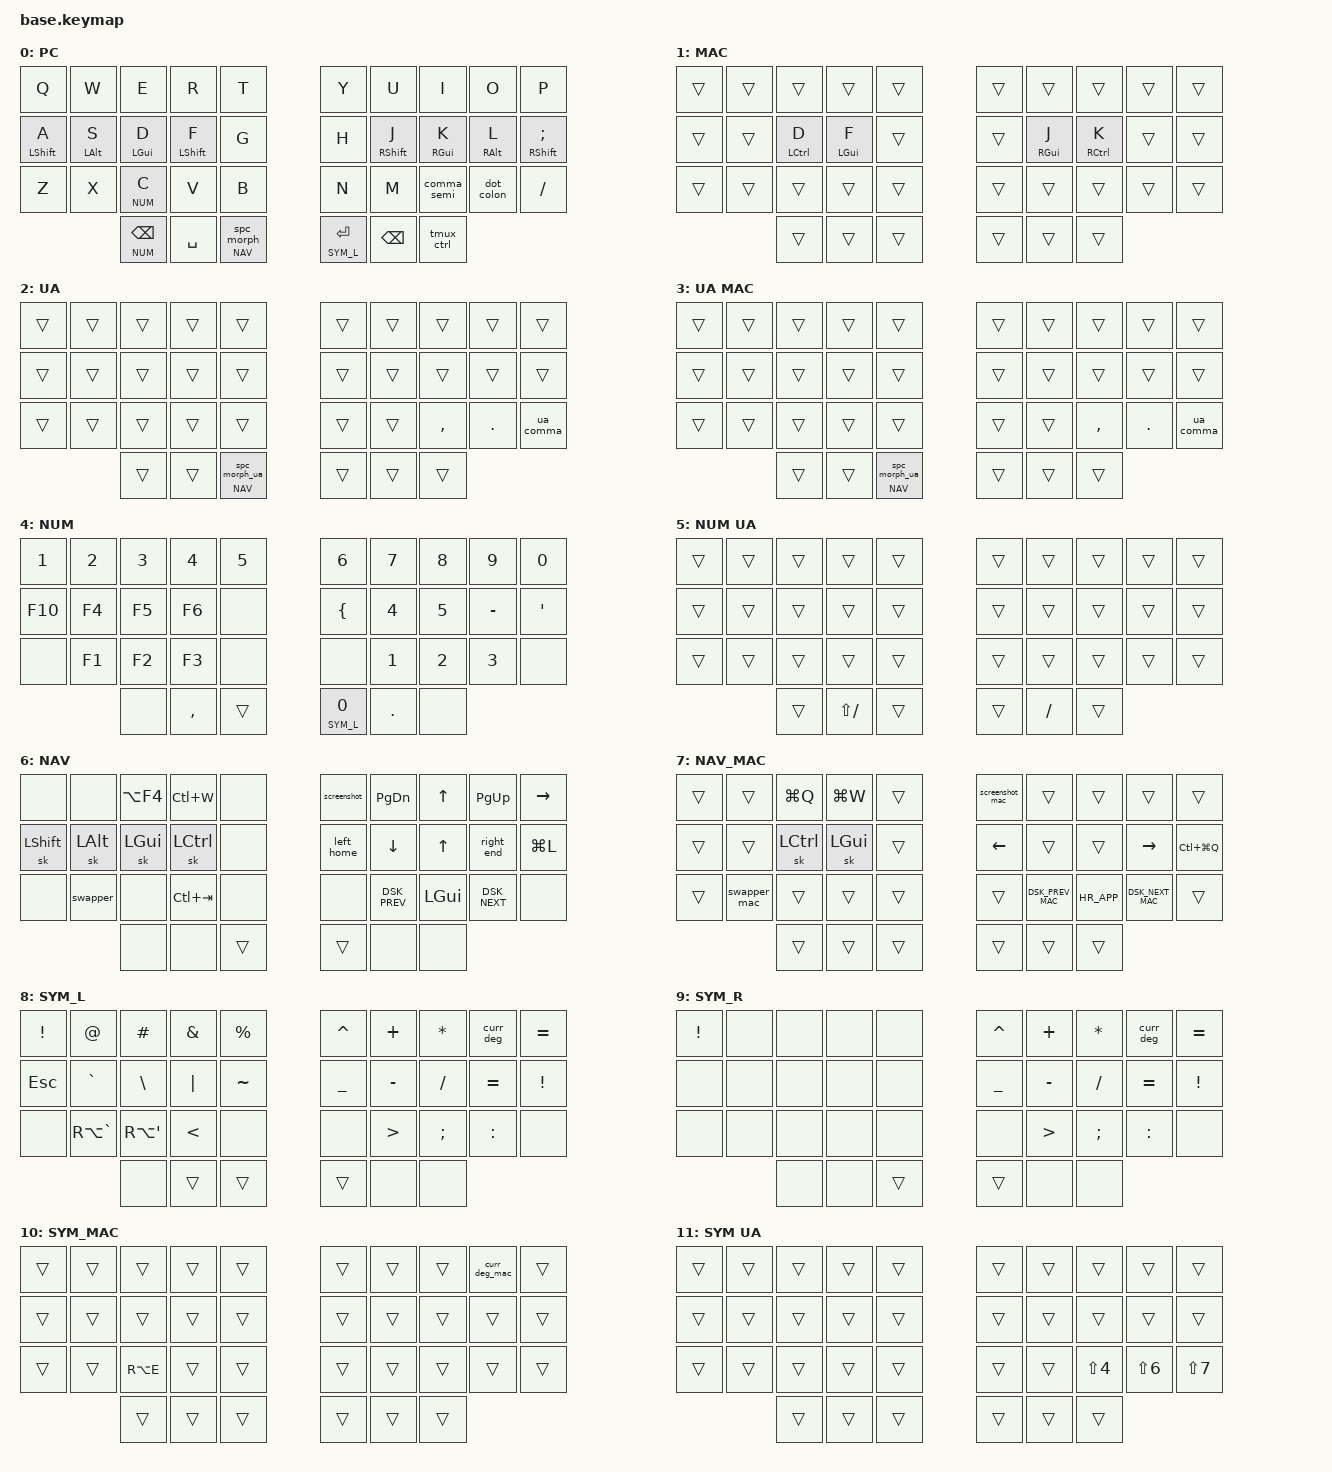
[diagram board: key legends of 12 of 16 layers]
#include <behaviors.dtsi>
#include <dt-bindings/zmk/keys.h>
#include <dt-bindings/zmk/outputs.h>

// ── LAYERS ────────────────────────────────────────────────────────────────────

// BASE = PC (Linux/Windows) is the default layer: resets and deep-sleep wake land here.
// BASE_MAC is an overlay that swaps Ctrl/GUI back for macOS (turned on from ADJ).
// UA / UA_MAC: Ukrainian overlay, switched together with the computer's language (combo: right Space +
// right Ctrl). Two copies because combos only look at the highest layer: PC and Mac combos must differ.
#define BASE 0
#define BASE_MAC 1
#define UA 2
#define UA_MAC 3
#define NUM 4
#define NUM_UA 5
#define NAV 6
#define NAV_MAC 7
#define SYM_L 8
#define SYM_R 9
#define SYM_MAC 10
#define SYM_UA 11
#define CMD_NUM 12
#define CMD_NUM_MAC 13
#define ADJ 14
#define LOCKL 15

#define xxx &none
#define ___ &trans

// ── INCLUDES & BLUETOOTH ──────────────────────────────────────────────────────

#include "combos.dtsi"
#if WIRELESS
    #include <dt-bindings/zmk/bt.h>
    // one key = BT profile + OS layer: P0 KDE (PC), P1 Windows (PC), P2 Mac
    #define BTL1  &bt BT_CLR   &mac_connect  &win_connect  &kde_connect
    #define BTL2  xxx          &bt BT_SEL 4  &bt BT_SEL 3  &out OUT_TOG
#else
    #define BTL1  xxx   xxx   xxx   xxx
    #define BTL2  xxx   xxx   xxx   xxx
#endif

// ── TIMING ────────────────────────────────────────────────────────────────────

#define TAP_TERM_MS 200
#define QUICK_TAP_MS 125

// ── KEY SHORTCUTS ─────────────────────────────────────────────────────────────

// PC symbols assume host layout "English (US, intl., AltGr dead keys)" on KDE /
// "US-International" on Windows: AltGr+5 = €, AltGr+Shift+; = °
#define deg RA(LS(SEMI))
#define deg_mac RA(LS(N8))
// PC = Windows + KDE Plasma (same shortcuts), MAC = macOS
// Language switch: Win+Space on Windows and KDE (KDE: "Switch to Next Keyboard Layout" = Meta+Space),
// Ctrl+Space on macOS ("Select the previous input source").
// Ukrainian host layout: KDE "Ukrainian" (ua), Windows "Ukrainian (Enhanced)". Same keys for all letters;
// . on the / key, , on Shift+/, ' on the ` key; ґ = AltGr+г on both (RA(U)).
#define LANG_PC LG(SPACE)
#define LANG_MAC LC(SPACE)
#define HR_APP LG(LS(SPACE))
#define DSK_PREV LG(LC(LEFT))
#define DSK_NEXT LG(LC(RIGHT))
#define DSK_PREV_MAC LC(LEFT)
#define DSK_NEXT_MAC LC(RIGHT)

// ── KEY POSITIONS (for homerow mods) ──────────────────────────────────────────
//  ╭─────────────────────╮ ╭─────────────────────╮
//  │  00  01  02  03  04 │ │  05  06  07  08  09 │
//  │  10  11  12  13  14 │ │  15  16  17  18  19 │
//  │  20  21  22  23  24 │ │  25  26  27  28  29 │
//  ╰───────╮  30  31  32 │ │  33  34  35 ╭───────╯
//          ╰─────────────╯ ╰─────────────╯

#define LEFT_KEYS  0 1 2 3 4 10 11 12 13 14 20 21 22 23 24
#define RIGHT_KEYS 5 6 7 8 9 15 16 17 18 19 25 26 27 28 29
#define THUMBS     30 31 32 33 34 35

// ── GLOBAL BEHAVIOR OVERRIDES ─────────────────────────────────────────────────

&lt {
    flavor = "balanced";
    tapping-term-ms = <TAP_TERM_MS>;
    quick-tap-ms = <QUICK_TAP_MS>;
};

&sk {
    release-after-ms = <1000>;
    quick-release;
};

&sl {
    release-after-ms = <5000>;
};

&caps_word {
    continue-list = <UNDERSCORE MINUS BSPC N1 N2 N3 N4 N5 N6 N7 N8 N9 N0>;
};

// ── MAIN TREE ─────────────────────────────────────────────────────────────────

/ {
    behaviors {

        // ── HOMEROW MODS (timeless) ───────────────────────────────────────────
        // Only trigger hold when the *opposite* hand presses a key,
        // and only if there was an idle gap before the HRM key.

        hml: left_hand_positional_hold_tap {
            compatible = "zmk,behavior-hold-tap";
            label = "LEFT_POSITIONAL_HOLD_TAP";
            #binding-cells = <2>;
            flavor = "balanced";
            tapping-term-ms = <TAP_TERM_MS>;
            quick-tap-ms = <QUICK_TAP_MS>;
            require-prior-idle-ms = <100>;
            bindings = <&kp>, <&kp>;
            hold-trigger-key-positions = <RIGHT_KEYS THUMBS>;
            hold-trigger-on-release;
        };

        hmr: right_hand_positional_hold_tap {
            compatible = "zmk,behavior-hold-tap";
            label = "RIGHT_POSITIONAL_HOLD_TAP";
            #binding-cells = <2>;
            flavor = "balanced";
            tapping-term-ms = <TAP_TERM_MS>;
            quick-tap-ms = <QUICK_TAP_MS>;
            require-prior-idle-ms = <100>;
            bindings = <&kp>, <&kp>;
            hold-trigger-key-positions = <LEFT_KEYS THUMBS>;
            hold-trigger-on-release;
        };

        // GUI variants: retro-tap, so a lone hold types the letter instead of
        // popping the Start menu / KDE launcher.
        hml_gui: left_hand_positional_hold_tap_gui {
            compatible = "zmk,behavior-hold-tap";
            label = "LEFT_POSITIONAL_HOLD_TAP_GUI";
            #binding-cells = <2>;
            flavor = "balanced";
            tapping-term-ms = <TAP_TERM_MS>;
            quick-tap-ms = <QUICK_TAP_MS>;
            require-prior-idle-ms = <100>;
            bindings = <&kp>, <&kp>;
            hold-trigger-key-positions = <RIGHT_KEYS THUMBS>;
            hold-trigger-on-release;
            retro-tap;
        };

        hmr_gui: right_hand_positional_hold_tap_gui {
            compatible = "zmk,behavior-hold-tap";
            label = "RIGHT_POSITIONAL_HOLD_TAP_GUI";
            #binding-cells = <2>;
            flavor = "balanced";
            tapping-term-ms = <TAP_TERM_MS>;
            quick-tap-ms = <QUICK_TAP_MS>;
            require-prior-idle-ms = <100>;
            bindings = <&kp>, <&kp>;
            hold-trigger-key-positions = <LEFT_KEYS THUMBS>;
            hold-trigger-on-release;
            retro-tap;
        };

        // ── TAP DANCES ────────────────────────────────────────────────────────

        curr_deg: tap_dance_curr_deg { // $ → € → ° (PC, AltGr)
            compatible = "zmk,behavior-tap-dance";
            label = "TAP_DANCE_curr_deg";
            #binding-cells = <0>;
            tapping-term-ms = <TAP_TERM_MS>;
            bindings = <&kp DLLR>, <&kp RA(N5)>, <&kp deg>;
        };
        curr_deg_mac: tap_dance_curr_deg_mac { // $ → € → ° (Mac, Option)
            compatible = "zmk,behavior-tap-dance";
            label = "TAP_DANCE_curr_deg_mac";
            #binding-cells = <0>;
            tapping-term-ms = <TAP_TERM_MS>;
            bindings = <&kp DLLR>, <&kp LA(N5)>, <&kp deg_mac>;
        };
        screenshot: screenshot { // area (Win+Shift+S) → PrintScreen
            // KDE: bind Spectacle "Capture Rectangular Region" to Meta+Shift+S
            compatible = "zmk,behavior-tap-dance";
            label = "SCREENSHOT";
            #binding-cells = <0>;
            tapping-term-ms = <TAP_TERM_MS>;
            bindings = <&kp LG(LS(S))>, <&kp PSCRN>;
        };
        screenshot_mac: screenshot_mac { // area selector → full-screen
            compatible = "zmk,behavior-tap-dance";
            label = "SCREENSHOT_MAC";
            #binding-cells = <0>;
            tapping-term-ms = <TAP_TERM_MS>;
            bindings = <&kp LG(LS(NUMBER_4))>, <&kp LG(LS(NUMBER_3))>;
        };
        tmux_ctrl: tmux_ctrl {
            compatible = "zmk,behavior-tap-dance";
            label = "TMUX_CTRL";
            #binding-cells = <0>;
            tapping-term-ms = <TAP_TERM_MS>;
            bindings = <&kp RCTRL>, <&tmux_num>;
        };
        space_cmd_num: space_cmd_num {
            compatible = "zmk,behavior-tap-dance";
            label = "SPACE_CMD_NUM";
            #binding-cells = <0>;
            tapping-term-ms = <TAP_TERM_MS>;
            bindings = <&kp SPACE>, <&mo CMD_NUM>;
        };

        // ── SMART SPACE (hold: layer | tap: space | shift+tap: ". " + sticky shift) ──

        spc_morph: spc_morph {
            compatible = "zmk,behavior-mod-morph";
            label = "SPC_MORPH";
            #binding-cells = <0>;
            bindings = <&kp SPACE>, <&dot_spc>;
            mods = <(MOD_LSFT)>;
        };
        lt_spc: lt_spc {
            compatible = "zmk,behavior-hold-tap";
            label = "LT_SPC";
            #binding-cells = <2>;
            tapping-term-ms = <TAP_TERM_MS>;
            quick-tap-ms = <QUICK_TAP_MS>;
            require-prior-idle-ms = <150>;  // mid-typing press is always Space
            retro-tap;                      // held too long, no other key: still Space
            flavor = "balanced";
            bindings = <&mo>, <&spc_morph>;
        };

        // ── ALT-TAB SWAPPER (tri-state: Cmd+Tab) ────────────────────────────

        swapper: swapper { // PC: Alt+Tab
            compatible = "zmk,behavior-tri-state";
            label = "SWAPPER";
            #binding-cells = <0>;
            bindings = <&kt LALT>, <&kp TAB>, <&kt LALT>;
            ignored-key-positions = <31>;
        };
        swapper_mac: swapper_mac { // Mac: Cmd+Tab
            compatible = "zmk,behavior-tri-state";
            label = "SWAPPER_MAC";
            #binding-cells = <0>;
            bindings = <&kt LGUI>, <&kp TAB>, <&kt LGUI>;
            ignored-key-positions = <31>;
        };

        // ── PC ARROWS WITH MAC MUSCLE MEMORY ─────────────────────────────────
        // Alt+←/→ → Ctrl+←/→ (word), Ctrl+←/→ → Home/End (line)

        left_home: left_home {
            compatible = "zmk,behavior-mod-morph";
            label = "LEFT_HOME";
            #binding-cells = <0>;
            bindings = <&kp LEFT>, <&left_home_nested>;
            keep-mods = <(MOD_LCTL|MOD_RCTL)>;
            mods = <(MOD_LCTL|MOD_RCTL|MOD_LALT|MOD_RALT)>;
        };
        left_home_nested: left_home_nested {
            compatible = "zmk,behavior-mod-morph";
            label = "LEFT_HOME_NESTED";
            #binding-cells = <0>;
            bindings = <&kp LC(LEFT)>, <&kp HOME>;
            mods = <(MOD_LCTL|MOD_RCTL)>;
        };
        right_end: right_end {
            compatible = "zmk,behavior-mod-morph";
            label = "RIGHT_END";
            #binding-cells = <0>;
            bindings = <&kp RIGHT>, <&right_end_nested>;
            keep-mods = <(MOD_LCTL|MOD_RCTL)>;
            mods = <(MOD_LCTL|MOD_RCTL|MOD_LALT|MOD_RALT)>;
        };
        right_end_nested: right_end_nested {
            compatible = "zmk,behavior-mod-morph";
            label = "RIGHT_END_NESTED";
            #binding-cells = <0>;
            bindings = <&kp LC(RIGHT)>, <&kp END>;
            mods = <(MOD_LCTL|MOD_RCTL)>;
        };

        // ── MOD-MORPHS (shift changes symbol) ────────────────────────────────

        dot_colon: dot_colon { // . → :
            compatible = "zmk,behavior-mod-morph";
            label = "DOT_TO_COLON";
            #binding-cells = <0>;
            bindings = <&kp DOT>, <&kp COLON>;
            mods = <(MOD_LSFT|MOD_RSFT)>;
        };
        comma_semi: comma_semi { // , → ;
            compatible = "zmk,behavior-mod-morph";
            label = "COMMA_TO_SEMICOLON";
            #binding-cells = <0>;
            bindings = <&kp COMMA>, <&kp SEMICOLON>;
            mods = <(MOD_LSFT|MOD_RSFT)>;
        };
        single_to_doublequote: single_to_doublequote { // ' → "
            compatible = "zmk,behavior-mod-morph";
            label = "SINGLE_TO_DOUBLEQUOTE";
            #binding-cells = <0>;
            bindings = <&kp SINGLE_QUOTE>, <&kp DOUBLE_QUOTES>;
            mods = <(MOD_LSFT|MOD_RSFT)>;
        };

        // ── UKRAINIAN ─────────────────────────────────────────────────────────
        ua_comma: ua_comma { // UA layout: , = Shift+/ (tap), . = / (Shift)
            compatible = "zmk,behavior-mod-morph";
            label = "UA_COMMA";
            #binding-cells = <0>;
            bindings = <&kp LS(SLASH)>, <&kp SLASH>;
            mods = <(MOD_LSFT|MOD_RSFT)>;
        };
        spc_morph_ua: spc_morph_ua { // Shift+Space = ". " + capital in UA (period is the / key)
            compatible = "zmk,behavior-mod-morph";
            label = "SPC_MORPH_UA";
            #binding-cells = <0>;
            bindings = <&kp SPACE>, <&dot_spc_ua>;
            mods = <(MOD_LSFT)>;
        };
        lt_spc_ua: lt_spc_ua {
            compatible = "zmk,behavior-hold-tap";
            label = "LT_SPC_UA";
            #binding-cells = <2>;
            tapping-term-ms = <TAP_TERM_MS>;
            quick-tap-ms = <QUICK_TAP_MS>;
            flavor = "balanced";
            bindings = <&mo>, <&spc_morph_ua>;
        };
    };

    // ── MACROS ────────────────────────────────────────────────────────────────

    macros {
        // delete entire line (PC): End → Shift+Home → Backspace
        del_line: del_line {
            label = "ZMK_DEL_LINE";
            compatible = "zmk,behavior-macro";
            #binding-cells = <0>;
            bindings
                = <&macro_tap &kp END>
                , <&macro_press &kp LSHFT>
                , <&macro_tap &kp HOME>
                , <&macro_release &kp LSHFT>
                , <&macro_tap &kp BSPC>
                ;
        };

        // delete entire line (Mac): End → Cmd+Home → Backspace
        del_line_mac: del_line_mac {
            label = "ZMK_DEL_LINE_MAC";
            compatible = "zmk,behavior-macro";
            #binding-cells = <0>;
            bindings
                = <&macro_press &kp END>
                , <&macro_press &kp LGUI>
                , <&macro_tap &kp HOME>
                , <&macro_release &kp LGUI>
                , <&macro_tap &kp BSPC>
                ;
        };

        // sentence ending: types ". " then activates sticky shift
        dot_spc: dot_spc {
            label = "ZM_DOT_SPACE";
            compatible = "zmk,behavior-macro";
            #binding-cells = <0>;
            wait-ms = <0>;
            tap-ms = <5>;
            bindings = <&kp DOT &kp SPACE &sk LSHFT>;
        };
        dot_spc_ua: dot_spc_ua { // same in the UA layout: period is the / key
            label = "ZM_DOT_SPACE_UA";
            compatible = "zmk,behavior-macro";
            #binding-cells = <0>;
            wait-ms = <0>;
            tap-ms = <5>;
            bindings = <&kp SLASH &kp SPACE &sk LSHFT>;
        };

        // language switch: computer shortcut + Ukrainian layer, so letters and punctuation follow
        lang_pc: lang_pc {
            label = "LANG_PC";
            compatible = "zmk,behavior-macro";
            #binding-cells = <0>;
            bindings = <&kp LANG_PC &tog UA>;
        };
        lang_mac: lang_mac {
            label = "LANG_MAC";
            compatible = "zmk,behavior-macro";
            #binding-cells = <0>;
            bindings = <&kp LANG_MAC &tog UA_MAC>;
        };

#if WIRELESS
        // select BT profile and the matching OS layer in one keypress
        kde_connect: kde_connect {
            label = "KDE_CONNECT";
            compatible = "zmk,behavior-macro";
            #binding-cells = <0>;
            bindings = <&bt BT_SEL 0 &to BASE>;
        };
        win_connect: win_connect {
            label = "WIN_CONNECT";
            compatible = "zmk,behavior-macro";
            #binding-cells = <0>;
            bindings = <&bt BT_SEL 1 &to BASE>;
        };
        mac_connect: mac_connect {
            label = "MAC_CONNECT";
            compatible = "zmk,behavior-macro";
            #binding-cells = <0>;
            bindings = <&bt BT_SEL 2 &to BASE_MAC>;
        };
#endif

        // tmux window selection: send prefix, then enable NUM for one keypress
        tmux_num: tmux_num {
            label = "TMUX_NUM";
            compatible = "zmk,behavior-macro";
            #binding-cells = <0>;
            bindings = <&kp LC(A) &sl NUM>;
        };
    };

    // ── CONDITIONAL LAYERS ────────────────────────────────────────────────────
    // NAV + SYM_L → ADJ (hold both layer thumbs)

    conditional_layers {
        compatible = "zmk,conditional-layers";
        tri_layer {
            if-layers = <NAV SYM_L>;
            then-layer = <ADJ>;
        };
        mac_nav { // Mac mode: NAV → NAV_MAC overrides
            if-layers = <BASE_MAC NAV>;
            then-layer = <NAV_MAC>;
        };
        mac_sym { // Mac mode: SYM_L → Option-based €, °, ´
            if-layers = <BASE_MAC SYM_L>;
            then-layer = <SYM_MAC>;
        };
        mac_cmd_num { // Mac mode: CMD_NUM → Cmd+1…0
            if-layers = <BASE_MAC CMD_NUM>;
            then-layer = <CMD_NUM_MAC>;
        };
        ua_num { // Ukrainian: decimal , and . on the UA keys
            if-layers = <UA NUM>;
            then-layer = <NUM_UA>;
        };
        ua_mac_num {
            if-layers = <UA_MAC NUM>;
            then-layer = <NUM_UA>;
        };
        ua_sym { // Ukrainian: ; : ? on the same SYM keys as in English
            if-layers = <UA SYM_L>;
            then-layer = <SYM_UA>;
        };
        ua_mac_sym {
            if-layers = <UA_MAC SYM_L>;
            then-layer = <SYM_UA>;
        };
    };

    // ── KEYMAP ────────────────────────────────────────────────────────────────

    keymap {
        compatible = "zmk,keymap";

        default_layer { // PC: Ctrl on index, GUI on middle finger
            label = "PC";
            bindings = <
             //╭──────────────┬──────────────┬──────────────┬──────────────┬──────────────╮     ╭──────────────┬──────────────┬──────────────┬──────────────┬──────────────╮
                &kp Q            &kp W          &kp E          &kp R         &kp T                 &kp Y          &kp U          &kp I          &kp O          &kp P
             //├──────────────┼──────────────┼──────────────┼──────────────┼──────────────┤     ├──────────────┼──────────────┼──────────────┼──────────────┼──────────────┤
                &hml LSHIFT A   &hml LALT S  &hml_gui LGUI D &hml LSHIFT F  &kp G                 &kp H          &hmr RSHIFT J   &hmr_gui RGUI K &hmr RALT L  &hmr RSHIFT SEMI
             //├──────────────┼──────────────┼──────────────┼──────────────┼──────────────┤     ├──────────────┼──────────────┼──────────────┼──────────────┼──────────────┤
                &kp Z            &kp X          &lt NUM C      &kp V          &kp B                &kp N            &kp M        &comma_semi    &dot_colon     &kp SLASH
             //╰──────────────┴──────────────┼──────────────┼──────────────┼──────────────┤     ├──────────────┼──────────────┼──────────────┼──────────────┴──────────────╯
                                              &lt NUM BSPC    &kp SPACE      &lt_spc NAV 0        &lt SYM_L RET  &kp BACKSPACE &tmux_ctrl
             //                              ╰──────────────┴──────────────┴──────────────╯     ╰──────────────┴──────────────┴──────────────╯
            >;
        };

        base_mac_layer { // macOS overlay: Cmd on index, Ctrl on middle finger
            label = "MAC";
            bindings = <
             //╭──────────────┬──────────────┬──────────────┬──────────────┬──────────────╮     ╭──────────────┬──────────────┬──────────────┬──────────────┬──────────────╮
                ___            ___            ___            ___            ___                  ___            ___            ___            ___            ___
             //├──────────────┼──────────────┼──────────────┼──────────────┼──────────────┤     ├──────────────┼──────────────┼──────────────┼──────────────┼──────────────┤
                ___            ___            &hml LCTRL D   &hml_gui LGUI F ___                  ___            &hmr_gui RGUI J &hmr RCTRL K  ___            ___
             //├──────────────┼──────────────┼──────────────┼──────────────┼──────────────┤     ├──────────────┼──────────────┼──────────────┼──────────────┼──────────────┤
                ___            ___            ___            ___            ___                  ___            ___            ___            ___            ___
             //╰──────────────┴──────────────┼──────────────┼──────────────┼──────────────┤     ├──────────────┼──────────────┼──────────────┼──────────────┴──────────────╯
                                              ___            ___            ___                  ___            ___            ___
             //                              ╰──────────────┴──────────────┴──────────────╯     ╰──────────────┴──────────────┴──────────────╯
            >;
        };

        ua_layer { // Ukrainian overlay (PC): б ю on , . — , and . on the / key; х ї є ґ ʼ are combos
            label = "UA";
            bindings = <
                ___             ___             ___             ___             ___             ___             ___             ___             ___             ___
                ___             ___             ___             ___             ___             ___             ___             ___             ___             ___
                ___             ___             ___             ___             ___             ___             ___             &kp COMMA       &kp DOT         &ua_comma
                ___             ___             &lt_spc_ua NAV 0  ___             ___             ___
            >;
        };

        ua_mac_layer { // Ukrainian overlay (Mac mode): same keys, Mac combos
            label = "UA MAC";
            bindings = <
                ___             ___             ___             ___             ___             ___             ___             ___             ___             ___
                ___             ___             ___             ___             ___             ___             ___             ___             ___             ___
                ___             ___             ___             ___             ___             ___             ___             &kp COMMA       &kp DOT         &ua_comma
                ___             ___             &lt_spc_ua NAV 0  ___             ___             ___
            >;
        };

        num_layer {
            label = "NUM";
            bindings = <
             //╭──────────────┬──────────────┬──────────────┬──────────────┬──────────────╮     ╭──────────────┬──────────────┬──────────────┬──────────────┬──────────────╮
                &kp N1         &kp N2         &kp N3         &kp N4         &kp N5               &kp N6         &kp N7         &kp N8         &kp N9         &kp N0
             //├──────────────┼──────────────┼──────────────┼──────────────┼──────────────┤     ├──────────────┼──────────────┼──────────────┼──────────────┼──────────────┤
                &kp F10        &kp F4         &kp F5         &kp F6         xxx                  &kp LBRC       &kp N4      &kp N5      &kp MINUS      &kp SQT
             //├──────────────┼──────────────┼──────────────┼──────────────┼──────────────┤     ├──────────────┼──────────────┼──────────────┼──────────────┼──────────────┤
                xxx            &kp F1         &kp F2         &kp F3         xxx                  xxx            &kp N1      &kp N2      &kp N3      xxx
             //╰──────────────┴──────────────┼──────────────┼──────────────┼──────────────┤     ├──────────────┼──────────────┼──────────────┼──────────────┴──────────────╯
                                              xxx            &kp COMMA      ___                  &lt SYM_L N0 &kp DOT       xxx
             //                              ╰──────────────┴──────────────┴──────────────╯     ╰──────────────┴──────────────┴──────────────╯
            >;
        };

        num_ua_layer { // Ukrainian NUM overrides (auto: UA + NUM): decimal , and .
            label = "NUM UA";
            bindings = <
                ___             ___             ___             ___             ___             ___             ___             ___             ___             ___
                ___             ___             ___             ___             ___             ___             ___             ___             ___             ___
                ___             ___             ___             ___             ___             ___             ___             ___             ___             ___
                ___             &kp LS(SLASH)   ___             ___             &kp SLASH       ___
            >;
        };

        nav_layer { // PC (Windows + KDE)
            label = "NAV";
            bindings = <
             //╭──────────────┬──────────────┬──────────────┬──────────────┬──────────────╮     ╭──────────────┬──────────────┬──────────────┬──────────────┬──────────────╮
                xxx            xxx            &kp LA(F4)     &kp LC(W)      xxx                  &screenshot    &kp PG_DN      &kp UP         &kp PG_UP      &kp RIGHT
             //├──────────────┼──────────────┼──────────────┼──────────────┼──────────────┤     ├──────────────┼──────────────┼──────────────┼──────────────┼──────────────┤
                &sk LSHFT      &sk LALT       &sk LGUI       &sk LCTRL      xxx                  &left_home     &kp DOWN       &kp UP         &right_end     &kp LG(L)
             //├──────────────┼──────────────┼──────────────┼──────────────┼──────────────┤     ├──────────────┼──────────────┼──────────────┼──────────────┼──────────────┤
                xxx            &swapper       xxx            &kp LC(TAB)    xxx                  xxx            &kp DSK_PREV   &kp LGUI       &kp DSK_NEXT   xxx
             //╰──────────────┴──────────────┼──────────────┼──────────────┼──────────────┤     ├──────────────┼──────────────┼──────────────┼──────────────┴──────────────╯
                                              xxx            xxx            ___                  ___            xxx            xxx
             //                              ╰──────────────┴──────────────┴──────────────╯     ╰──────────────┴──────────────┴──────────────╯
            >;
        };

        nav_mac_layer { // Mac overrides on NAV (auto: MAC + NAV)
            label = "NAV_MAC";
            bindings = <
             //╭──────────────┬──────────────┬──────────────┬──────────────┬──────────────╮     ╭──────────────┬──────────────┬──────────────┬──────────────┬──────────────╮
                ___            ___            &kp LG(Q)      &kp LG(W)      ___                  &screenshot_mac ___           ___            ___            ___
             //├──────────────┼──────────────┼──────────────┼──────────────┼──────────────┤     ├──────────────┼──────────────┼──────────────┼──────────────┼──────────────┤
                ___            ___            &sk LCTRL      &sk LGUI       ___                  &kp LEFT       ___            ___            &kp RIGHT      &kp LC(LG(Q))
             //├──────────────┼──────────────┼──────────────┼──────────────┼──────────────┤     ├──────────────┼──────────────┼──────────────┼──────────────┼──────────────┤
                ___            &swapper_mac   ___            ___            ___                  ___            &kp DSK_PREV_MAC &kp HR_APP   &kp DSK_NEXT_MAC ___
             //╰──────────────┴──────────────┼──────────────┼──────────────┼──────────────┤     ├──────────────┼──────────────┼──────────────┼──────────────┴──────────────╯
                                              ___            ___            ___                  ___            ___            ___
             //                              ╰──────────────┴──────────────┴──────────────╯     ╰──────────────┴──────────────┴──────────────╯
            >;
        };

        symbols_left { // activated by right thumb — symbols on both hands
            label = "SYM_L";
            bindings = <
             //╭──────────────┬──────────────┬──────────────┬──────────────┬──────────────╮     ╭──────────────┬──────────────┬──────────────┬──────────────┬──────────────╮
                &kp EXCL       &kp AT         &kp HASH       &kp AMPS       &kp PERCENT          &kp CARET      &kp PLUS       &kp ASTRK      &curr_deg      &kp EQUAL
             //├──────────────┼──────────────┼──────────────┼──────────────┼──────────────┤     ├──────────────┼──────────────┼──────────────┼──────────────┼──────────────┤
                &kp ESCAPE     &kp GRAVE      &kp BSLH       &kp PIPE       &kp TILDE            &kp UNDER      &kp MINUS      &kp SLASH      &kp EQUAL      &kp EXCL
             //├──────────────┼──────────────┼──────────────┼──────────────┼──────────────┤     ├──────────────┼──────────────┼──────────────┼──────────────┼──────────────┤
                xxx            &kp RA(GRAVE)  &kp RA(SQT)    &kp LT         xxx                  xxx            &kp GT         &kp SEMI       &kp COLON      xxx
             //╰──────────────┴──────────────┼──────────────┼──────────────┼──────────────┤     ├──────────────┼──────────────┼──────────────┼──────────────┴──────────────╯
                                              xxx            ___            ___                  ___            xxx            xxx
             //                              ╰──────────────┴──────────────┴──────────────╯     ╰──────────────┴──────────────┴──────────────╯
            >;
        };

        symbols_right { // activated by left thumb — right-hand symbols
            label = "SYM_R";
            bindings = <
             //╭──────────────┬──────────────┬──────────────┬──────────────┬──────────────╮     ╭──────────────┬──────────────┬──────────────┬──────────────┬──────────────╮
                &kp EXCL       xxx            xxx            xxx            xxx                  &kp CARET      &kp PLUS       &kp ASTRK      &curr_deg      &kp EQUAL
             //├──────────────┼──────────────┼──────────────┼──────────────┼──────────────┤     ├──────────────┼──────────────┼──────────────┼──────────────┼──────────────┤
                xxx            xxx            xxx            xxx            xxx                  &kp UNDER      &kp MINUS      &kp SLASH      &kp EQUAL      &kp EXCL
             //├──────────────┼──────────────┼──────────────┼──────────────┼──────────────┤     ├──────────────┼──────────────┼──────────────┼──────────────┼──────────────┤
                xxx            xxx            xxx            xxx            xxx                  xxx            &kp GT         &kp SEMI       &kp COLON      xxx
             //╰──────────────┴──────────────┼──────────────┼──────────────┼──────────────┤     ├──────────────┼──────────────┼──────────────┼──────────────┴──────────────╯
                                              xxx            xxx            ___                  ___            xxx            xxx
             //                              ╰──────────────┴──────────────┴──────────────╯     ╰──────────────┴──────────────┴──────────────╯
            >;
        };

        symbols_mac { // Mac overrides on SYM_L (auto: MAC + SYM_L)
            label = "SYM_MAC";
            bindings = <
             //╭──────────────┬──────────────┬──────────────┬──────────────┬──────────────╮     ╭──────────────┬──────────────┬──────────────┬──────────────┬──────────────╮
                ___            ___            ___            ___            ___                  ___            ___            ___            &curr_deg_mac  ___
             //├──────────────┼──────────────┼──────────────┼──────────────┼──────────────┤     ├──────────────┼──────────────┼──────────────┼──────────────┼──────────────┤
                ___            ___            ___            ___            ___                  ___            ___            ___            ___            ___
             //├──────────────┼──────────────┼──────────────┼──────────────┼──────────────┤     ├──────────────┼──────────────┼──────────────┼──────────────┼──────────────┤
                ___            ___            &kp RA(E)      ___            ___                  ___            ___            ___            ___            ___
             //╰──────────────┴──────────────┼──────────────┼──────────────┼──────────────┤     ├──────────────┼──────────────┼──────────────┼──────────────┴──────────────╯
                                              ___            ___            ___                  ___            ___            ___
             //                              ╰──────────────┴──────────────┴──────────────╯     ╰──────────────┴──────────────┴──────────────╯
            >;
        };

        symbols_ua { // Ukrainian SYM overrides (auto: UA + SYM_L): ; : ? like in English
            label = "SYM UA";
            bindings = <
                ___             ___             ___             ___             ___             ___             ___             ___             ___             ___
                ___             ___             ___             ___             ___             ___             ___             ___             ___             ___
                ___             ___             ___             ___             ___             ___             ___             &kp LS(N4)      &kp LS(N6)      &kp LS(N7)
                ___             ___             ___             ___             ___             ___
            >;
        };

        cmd_num_layer { // PC: Ctrl+1…0 (browser tab N)
            label = "CMD_NUM";
            bindings = <
             //╭──────────────┬──────────────┬──────────────┬──────────────┬──────────────╮     ╭──────────────┬──────────────┬──────────────┬──────────────┬──────────────╮
                &kp LC(N1)     &kp LC(N2)     &kp LC(N3)     &kp LC(N4)     &kp LC(N5)           &kp LC(N6)     &kp LC(N7)     &kp LC(N8)     &kp LC(N9)     &kp LC(N0)
             //├──────────────┼──────────────┼──────────────┼──────────────┼──────────────┤     ├──────────────┼──────────────┼──────────────┼──────────────┼──────────────┤
                xxx            xxx            xxx            xxx            xxx                  xxx            xxx            xxx            xxx            xxx
             //├──────────────┼──────────────┼──────────────┼──────────────┼──────────────┤     ├──────────────┼──────────────┼──────────────┼──────────────┼──────────────┤
                xxx            xxx            xxx            xxx            xxx                  xxx            xxx            xxx            xxx            xxx
             //╰──────────────┴──────────────┼──────────────┼──────────────┼──────────────┤     ├──────────────┼──────────────┼──────────────┴──────────────┴──────────────╯
                                              xxx            xxx            xxx                  xxx            xxx            xxx
             //                              ╰──────────────┴──────────────┴──────────────╯     ╰──────────────┴──────────────┴──────────────╯
            >;
        };

        cmd_num_mac_layer { // Mac: Cmd+1…0 (auto: MAC + CMD_NUM)
            label = "CMD_MAC";
            bindings = <
             //╭──────────────┬──────────────┬──────────────┬──────────────┬──────────────╮     ╭──────────────┬──────────────┬──────────────┬──────────────┬──────────────╮
                &kp LG(N1)     &kp LG(N2)     &kp LG(N3)     &kp LG(N4)     &kp LG(N5)           &kp LG(N6)     &kp LG(N7)     &kp LG(N8)     &kp LG(N9)     &kp LG(N0)
             //├──────────────┼──────────────┼──────────────┼──────────────┼──────────────┤     ├──────────────┼──────────────┼──────────────┼──────────────┼──────────────┤
                xxx            xxx            xxx            xxx            xxx                  xxx            xxx            xxx            xxx            xxx
             //├──────────────┼──────────────┼──────────────┼──────────────┼──────────────┤     ├──────────────┼──────────────┼──────────────┼──────────────┼──────────────┤
                xxx            xxx            xxx            xxx            xxx                  xxx            xxx            xxx            xxx            xxx
             //╰──────────────┴──────────────┼──────────────┼──────────────┼──────────────┤     ├──────────────┼──────────────┼──────────────┴──────────────┴──────────────╯
                                              xxx            xxx            xxx                  xxx            xxx            xxx
             //                              ╰──────────────┴──────────────┴──────────────╯     ╰──────────────┴──────────────┴──────────────╯
            >;
        };

        adj_layer { // conditional: NAV + SYM_L — system, media, bluetooth
            label = "ADJ";
            bindings = <
             //╭──────────────┬──────────────┬──────────────┬──────────────┬──────────────╮     ╭──────────────┬──────────────┬──────────────┬──────────────┬──────────────╮
                xxx            &soft_off      &to BASE       &to BASE_MAC   &bootloader          &bootloader    &kp C_PP       &kp C_NEXT     &kp C_PREV     xxx
             //├──────────────┼──────────────┼──────────────┼──────────────┼──────────────┤     ├──────────────┼──────────────┼──────────────┼──────────────┼──────────────┤
                BTL1                                                        &sys_reset           &sys_reset     &kp C_VOL_DN   &kp C_VOL_UP   &kp C_MUTE     xxx
             //├──────────────┼──────────────┼──────────────┼──────────────┼──────────────┤     ├──────────────┼──────────────┼──────────────┼──────────────┼──────────────┤
                BTL2                                                        xxx                  xxx            &kp C_BRI_DN   &kp C_BRI_UP   xxx            xxx
             //╰──────────────┴──────────────┼──────────────┼──────────────┼──────────────┤     ├──────────────┼──────────────┼──────────────┼──────────────┴──────────────╯
                                              xxx            xxx            xxx                  xxx            xxx            xxx
             //                              ╰──────────────┴──────────────┴──────────────╯     ╰──────────────┴──────────────┴──────────────╯
            >;
        };

        lock_layer {
            label = "LOCK";
            bindings = <
             //╭──────────────┬──────────────┬──────────────┬──────────────┬──────────────╮     ╭──────────────┬──────────────┬──────────────┬──────────────┬──────────────╮
                xxx            xxx            xxx            xxx            xxx                  xxx            xxx            xxx            xxx            xxx
             //├──────────────┼──────────────┼──────────────┼──────────────┼──────────────┤     ├──────────────┼──────────────┼──────────────┼──────────────┼──────────────┤
                xxx            xxx            xxx            xxx            xxx                  xxx            xxx            xxx            xxx            xxx
             //├──────────────┼──────────────┼──────────────┼──────────────┼──────────────┤     ├──────────────┼──────────────┼──────────────┼──────────────┼──────────────┤
                xxx            xxx            xxx            xxx            xxx                  xxx            xxx            xxx            xxx            xxx
             //╰──────────────┴──────────────┼──────────────┼──────────────┼──────────────┤     ├──────────────┼──────────────┼──────────────┼──────────────┴──────────────╯
                                              xxx            xxx            xxx                  xxx            xxx            xxx
             //                              ╰──────────────┴──────────────┴──────────────╯     ╰──────────────┴──────────────┴──────────────╯
            >;
        };

    };
};
